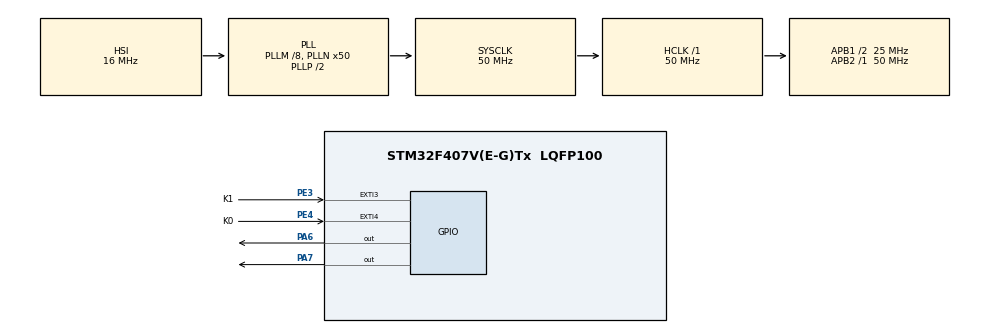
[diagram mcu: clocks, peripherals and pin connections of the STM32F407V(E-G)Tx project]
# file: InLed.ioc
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Mcu.Family=STM32F4
Mcu.Name=STM32F407V(E-G)Tx
Mcu.Package=LQFP100
NVIC.EXTI3_IRQn=true\:0\:0\:false\:false\:true\:true\:true\:true
NVIC.EXTI4_IRQn=true\:0\:0\:true\:false\:true\:true\:true\:true
NVIC.PriorityGroup=NVIC_PRIORITYGROUP_4
PA6.GPIO_ModeDefaultOutputPP=GPIO_MODE_OUTPUT_PP
PA6.GPIO_PuPd=GPIO_NOPULL
PA6.PinState=GPIO_PIN_RESET
PA6.Signal=GPIO_Output
PA7.Signal=GPIO_Output
PC14-OSC32_IN.Mode=LSE-External-Oscillator
PC14-OSC32_IN.Signal=RCC_OSC32_IN
PC15-OSC32_OUT.Mode=LSE-External-Oscillator
PC15-OSC32_OUT.Signal=RCC_OSC32_OUT
PE3.GPIO_Label=K1
PE3.GPIO_PuPd=GPIO_PULLUP
PE3.Signal=GPXTI3
PE4.GPIO_Label=K0
PE4.GPIO_ModeDefaultEXTI=GPIO_MODE_IT_FALLING
PE4.GPIO_PuPd=GPIO_PULLUP
PE4.Signal=GPXTI4
PH0-OSC_IN.Mode=HSE-External-Clock-Source
PH0-OSC_IN.Signal=RCC_OSC_IN
PH1-OSC_OUT.Mode=HSE-External-Clock-Source
PH1-OSC_OUT.Signal=RCC_OSC_OUT
ProjectManager.HeapSize=0x200
ProjectManager.StackSize=0x400
ProjectManager.TargetToolchain=STM32CubeIDE
RCC.48MHZClocksFreq_Value=25000000
RCC.AHBFreq_Value=50000000
RCC.APB1CLKDivider=RCC_HCLK_DIV2
RCC.APB1Freq_Value=25000000
RCC.APB1TimFreq_Value=50000000
RCC.APB2Freq_Value=50000000
RCC.APB2TimFreq_Value=50000000
RCC.CortexFreq_Value=50000000
RCC.HCLKFreq_Value=50000000
RCC.HSE_VALUE=25000000
RCC.HSI_VALUE=16000000
RCC.PLLM=8
RCC.PLLN=50
RCC.SYSCLKFreq_VALUE=50000000
RCC.SYSCLKSource=RCC_SYSCLKSOURCE_PLLCLK
RCC.VCOOutputFreq_Value=100000000
VP_RTC_VS_RTC_Activate.Mode=RTC_Enabled
board=custom

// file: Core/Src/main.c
/* USER CODE BEGIN Header */
/**
  ******************************************************************************
  * @file           : main.c
  * @brief          : Main program body
  ******************************************************************************
  * @attention
  *
  * Copyright (c) 2025 STMicroelectronics.
  * All rights reserved.
  *
  * This software is licensed under terms that can be found in the LICENSE file
  * in the root directory of this software component.
  * If no LICENSE file comes with this software, it is provided AS-IS.
  *
  ******************************************************************************
  */
/* USER CODE END Header */
#include "main.h"

RTC_HandleTypeDef hrtc;

void SystemClock_Config(void);
static void MX_GPIO_Init(void);
static void MX_RTC_Init(void);

int main(void)
{

  /* MCU Configuration--------------------------------------------------------*/

  /* Reset of all peripherals, Initializes the Flash interface and the Systick. */
  HAL_Init();

  /* Configure the system clock */
  SystemClock_Config();

  /* Initialize all configured peripherals */
  MX_GPIO_Init();
  MX_RTC_Init();

  /* Infinite loop */
  while (1)
  {

  }
}

void SystemClock_Config(void)
{
  RCC_OscInitTypeDef RCC_OscInitStruct = {0};
  RCC_ClkInitTypeDef RCC_ClkInitStruct = {0};

  /** Configure the main internal regulator output voltage
  */
  __HAL_RCC_PWR_CLK_ENABLE();
  __HAL_PWR_VOLTAGESCALING_CONFIG(PWR_REGULATOR_VOLTAGE_SCALE1);

  /** Initializes the RCC Oscillators according to the specified parameters
  * in the RCC_OscInitTypeDef structure.
  */
  RCC_OscInitStruct.OscillatorType = RCC_OSCILLATORTYPE_HSI|RCC_OSCILLATORTYPE_LSI;
  RCC_OscInitStruct.HSIState = RCC_HSI_ON;
  RCC_OscInitStruct.HSICalibrationValue = RCC_HSICALIBRATION_DEFAULT;
  RCC_OscInitStruct.LSIState = RCC_LSI_ON;
  RCC_OscInitStruct.PLL.PLLState = RCC_PLL_ON;
  RCC_OscInitStruct.PLL.PLLSource = RCC_PLLSOURCE_HSI;
  RCC_OscInitStruct.PLL.PLLM = 8;
  RCC_OscInitStruct.PLL.PLLN = 50;
  RCC_OscInitStruct.PLL.PLLP = RCC_PLLP_DIV2;
  RCC_OscInitStruct.PLL.PLLQ = 4;
  if (HAL_RCC_OscConfig(&RCC_OscInitStruct) != HAL_OK)
  {
    Error_Handler();
  }

  /** Initializes the CPU, AHB and APB buses clocks
  */
  RCC_ClkInitStruct.ClockType = RCC_CLOCKTYPE_HCLK|RCC_CLOCKTYPE_SYSCLK
                              |RCC_CLOCKTYPE_PCLK1|RCC_CLOCKTYPE_PCLK2;
  RCC_ClkInitStruct.SYSCLKSource = RCC_SYSCLKSOURCE_PLLCLK;
  RCC_ClkInitStruct.AHBCLKDivider = RCC_SYSCLK_DIV1;
  RCC_ClkInitStruct.APB1CLKDivider = RCC_HCLK_DIV2;
  RCC_ClkInitStruct.APB2CLKDivider = RCC_HCLK_DIV1;

  if (HAL_RCC_ClockConfig(&RCC_ClkInitStruct, FLASH_LATENCY_1) != HAL_OK)
  {
    Error_Handler();
  }
}

static void MX_RTC_Init(void)
{

  /** Initialize RTC Only
  */
  hrtc.Instance = RTC;
  hrtc.Init.HourFormat = RTC_HOURFORMAT_24;
  hrtc.Init.AsynchPrediv = 127;
  hrtc.Init.SynchPrediv = 255;
  hrtc.Init.OutPut = RTC_OUTPUT_DISABLE;
  hrtc.Init.OutPutPolarity = RTC_OUTPUT_POLARITY_HIGH;
  hrtc.Init.OutPutType = RTC_OUTPUT_TYPE_OPENDRAIN;
  if (HAL_RTC_Init(&hrtc) != HAL_OK)
  {
    Error_Handler();
  }

}

static void MX_GPIO_Init(void)
{
  GPIO_InitTypeDef GPIO_InitStruct = {0};

  /* GPIO Ports Clock Enable */
  __HAL_RCC_GPIOE_CLK_ENABLE();
  __HAL_RCC_GPIOC_CLK_ENABLE();
  __HAL_RCC_GPIOH_CLK_ENABLE();
  __HAL_RCC_GPIOA_CLK_ENABLE();

  /*Configure GPIO pin Output Level */
  HAL_GPIO_WritePin(GPIOA, GPIO_PIN_6|GPIO_PIN_7, GPIO_PIN_RESET);

  /*Configure GPIO pin : K1_Pin */
  GPIO_InitStruct.Pin = K1_Pin;
  GPIO_InitStruct.Mode = GPIO_MODE_IT_RISING;
  GPIO_InitStruct.Pull = GPIO_PULLUP;
  HAL_GPIO_Init(K1_GPIO_Port, &GPIO_InitStruct);

  /*Configure GPIO pin : K0_Pin */
  GPIO_InitStruct.Pin = K0_Pin;
  GPIO_InitStruct.Mode = GPIO_MODE_IT_RISING;
  GPIO_InitStruct.Pull = GPIO_PULLUP;
  HAL_GPIO_Init(K0_GPIO_Port, &GPIO_InitStruct);

  /*Configure GPIO pins : PA6 PA7 */
  GPIO_InitStruct.Pin = GPIO_PIN_6|GPIO_PIN_7;
  GPIO_InitStruct.Mode = GPIO_MODE_OUTPUT_PP;
  GPIO_InitStruct.Pull = GPIO_NOPULL;
  GPIO_InitStruct.Speed = GPIO_SPEED_FREQ_LOW;
  HAL_GPIO_Init(GPIOA, &GPIO_InitStruct);

  /* EXTI interrupt init*/
  HAL_NVIC_SetPriority(EXTI3_IRQn, 0, 0);
  HAL_NVIC_EnableIRQ(EXTI3_IRQn);

  HAL_NVIC_SetPriority(EXTI4_IRQn, 0, 0);
  HAL_NVIC_EnableIRQ(EXTI4_IRQn);

}

/* USER CODE BEGIN 4 */
void HAL_GPIO_EXTI_Callback(uint16_t GPIO_Pin)
{
    if (GPIO_Pin == K0_Pin)
    {
        HAL_GPIO_TogglePin(GPIOA, GPIO_PIN_6);
    }
    if (GPIO_Pin == K1_Pin)
    {
        HAL_GPIO_TogglePin(GPIOA, GPIO_PIN_7);
    }
}

/* USER CODE END 4 */

void Error_Handler(void)
{
  __disable_irq();
  while (1)
  {
  }
}
